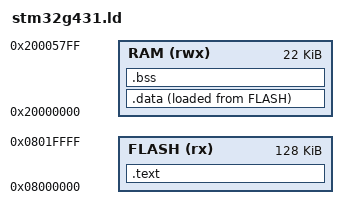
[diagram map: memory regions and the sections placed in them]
/* STM32G431CB：128 KB Flash，SRAM1 + SRAM2 共 22 KB（RM0440 存储器映射） */
MEMORY
{
  FLASH (rx) : ORIGIN = 0x08000000, LENGTH = 128K
  RAM (rwx) : ORIGIN = 0x20000000, LENGTH = 22K
}
_estack = ORIGIN(RAM) + LENGTH(RAM);
SECTIONS
{
  .text : { KEEP(*(.isr_vector)) *(.text*) *(.rodata*) . = ALIGN(4); } > FLASH
  _sidata = LOADADDR(.data);
  .data : { _sdata = .; *(.data*) . = ALIGN(4); _edata = .; } > RAM AT > FLASH
  .bss (NOLOAD) : { _sbss = .; *(.bss*) *(COMMON) . = ALIGN(4); _ebss = .; } > RAM
}
